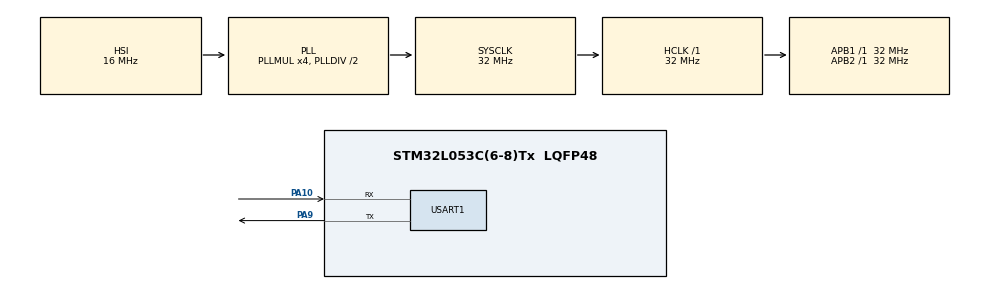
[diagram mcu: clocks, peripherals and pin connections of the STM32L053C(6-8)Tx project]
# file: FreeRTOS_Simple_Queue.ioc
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FREERTOS.Tasks01=defaultTask,0,128,StartDefaultTask,Default,NULL,Dynamic,NULL,NULL
Mcu.Family=STM32L0
Mcu.Name=STM32L053C(6-8)Tx
Mcu.Package=LQFP48
NVIC.TIM6_DAC_IRQn=true\:3\:0\:false\:false\:true\:false\:false\:true\:true
NVIC.TimeBase=TIM6_DAC_IRQn
NVIC.TimeBaseIP=TIM6
NVIC.USART1_IRQn=true\:3\:0\:false\:false\:true\:true\:true\:true\:true
PA10.Mode=Asynchronous
PA10.Signal=USART1_RX
PA9.Mode=Asynchronous
PA9.Signal=USART1_TX
ProjectManager.HeapSize=0x200
ProjectManager.StackSize=0x400
ProjectManager.TargetToolchain=STM32CubeIDE
RCC.AHBFreq_Value=32000000
RCC.APB1Freq_Value=32000000
RCC.APB1TimFreq_Value=32000000
RCC.APB2Freq_Value=32000000
RCC.APB2TimFreq_Value=32000000
RCC.HCLKFreq_Value=32000000
RCC.HSE_VALUE=8000000
RCC.HSI16_VALUE=16000000
RCC.HSI48MClockSelection=RCC_USBCLKSOURCE_HSI48
RCC.HSI48_VALUE=48000000
RCC.HSI_VALUE=16000000
RCC.LSE_VALUE=32768
RCC.MSI_VALUE=2097000
RCC.PLLMUL=RCC_PLLMUL_4
RCC.RTCClockSelectionVirtual=RCC_RTCCLKSOURCE_LSE
RCC.SYSCLKFreq_VALUE=32000000
RCC.SYSCLKSource=RCC_SYSCLKSOURCE_PLLCLK
RCC.VCOOutputFreq_Value=64000000
USART1.VirtualMode-Asynchronous=VM_ASYNC
VP_FREERTOS_VS_CMSIS_V1.Mode=CMSIS_V1
VP_SYS_VS_tim6.Mode=TIM6
board=STM32L0538-DISCO

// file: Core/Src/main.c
/* USER CODE BEGIN Header */
/**
 ******************************************************************************
 * @file           : main.c
 * @brief          : Main program body
 ******************************************************************************
 * @attention
 *
 * Copyright (c) 2023 STMicroelectronics.
 * All rights reserved.
 *
 * This software is licensed under terms that can be found in the LICENSE file
 * in the root directory of this software component.
 * If no LICENSE file comes with this software, it is provided AS-IS.
 *
 ******************************************************************************
 */
/* USER CODE END Header */
#include "main.h"

/* USER CODE BEGIN Includes */

#include "FreeRTOS.h"
#include "task.h"
#include "timers.h"
#include "queue.h"
#include "semphr.h"
#include "event_groups.h"

#include "string.h"
#include <stdio.h>
/* USER CODE END Includes */

UART_HandleTypeDef huart1;

/* USER CODE BEGIN PV */
uint8_t Rx_Data;
/* USER CODE END PV */

void SystemClock_Config(void);
static void MX_GPIO_Init(void);
static void MX_USART1_UART_Init(void);

/* USER CODE BEGIN 0 */

/************************* TASK HANDLERS **************************/
xTaskHandle Sender_HPT_Handler;
xTaskHandle Sender_LPT_Handler;
xTaskHandle Receiver_Handler;

/**********************  QUEUE HANDLER *********************/
xQueueHandle SimpleQueue;

/**********************  TASK FUNCTIONS *********************/
void Sender_HPT_Task(void *argument);
void Sender_LPT_Task(void *argument);
void Receiver_Task(void *argument);

/* USER CODE END 0 */

int main(void) {

	/* MCU Configuration--------------------------------------------------------*/

	/* Reset of all peripherals, Initializes the Flash interface and the Systick. */
	HAL_Init();

	/* Configure the system clock */
	SystemClock_Config();

	/* Initialize all configured peripherals */
	MX_GPIO_Init();
	MX_USART1_UART_Init();
	/* USER CODE BEGIN 2 */

	/**********************  Create Integer Queue *********************/
	SimpleQueue = xQueueCreate(5, sizeof(int));

	if (SimpleQueue == 0) {
		char *str = "OOPS!\r\nUnable ton create Integer Queue\r\n\r\n";
		HAL_UART_Transmit(&huart1, (uint8_t*) str, strlen(str), HAL_MAX_DELAY);
	} else {
		char *str = "Integer Queue created Successfully.\r\n\r\n";
		HAL_UART_Transmit(&huart1, (uint8_t*) str, strlen(str), HAL_MAX_DELAY);
	}

	/**********************  Create Task *********************/
	xTaskCreate(Sender_HPT_Task, "HPT_SEND", 128, NULL, 3, &Sender_HPT_Handler);
	xTaskCreate(Sender_LPT_Task, "LPT_SEND", 128, (void*) 111, 2,
			&Sender_LPT_Handler);
	xTaskCreate(Receiver_Task, "Receive", 128, NULL, 1, &Receiver_Handler);

	HAL_UART_Receive_IT(&huart1, &Rx_Data, 1);

	vTaskStartScheduler();

	/* USER CODE END 2 */

	/* Infinite loop */
	while (1) {

	}
}

void SystemClock_Config(void) {
	RCC_OscInitTypeDef RCC_OscInitStruct = { 0 };
	RCC_ClkInitTypeDef RCC_ClkInitStruct = { 0 };
	RCC_PeriphCLKInitTypeDef PeriphClkInit = { 0 };

	/** Configure the main internal regulator output voltage
	 */
	__HAL_PWR_VOLTAGESCALING_CONFIG(PWR_REGULATOR_VOLTAGE_SCALE1);

	/** Initializes the RCC Oscillators according to the specified parameters
	 * in the RCC_OscInitTypeDef structure.
	 */
	RCC_OscInitStruct.OscillatorType = RCC_OSCILLATORTYPE_HSI;
	RCC_OscInitStruct.HSIState = RCC_HSI_ON;
	RCC_OscInitStruct.HSICalibrationValue = RCC_HSICALIBRATION_DEFAULT;
	RCC_OscInitStruct.PLL.PLLState = RCC_PLL_ON;
	RCC_OscInitStruct.PLL.PLLSource = RCC_PLLSOURCE_HSI;
	RCC_OscInitStruct.PLL.PLLMUL = RCC_PLLMUL_4;
	RCC_OscInitStruct.PLL.PLLDIV = RCC_PLLDIV_2;
	if (HAL_RCC_OscConfig(&RCC_OscInitStruct) != HAL_OK) {
		Error_Handler();
	}

	/** Initializes the CPU, AHB and APB buses clocks
	 */
	RCC_ClkInitStruct.ClockType = RCC_CLOCKTYPE_HCLK | RCC_CLOCKTYPE_SYSCLK
			| RCC_CLOCKTYPE_PCLK1 | RCC_CLOCKTYPE_PCLK2;
	RCC_ClkInitStruct.SYSCLKSource = RCC_SYSCLKSOURCE_PLLCLK;
	RCC_ClkInitStruct.AHBCLKDivider = RCC_SYSCLK_DIV1;
	RCC_ClkInitStruct.APB1CLKDivider = RCC_HCLK_DIV1;
	RCC_ClkInitStruct.APB2CLKDivider = RCC_HCLK_DIV1;

	if (HAL_RCC_ClockConfig(&RCC_ClkInitStruct, FLASH_LATENCY_1) != HAL_OK) {
		Error_Handler();
	}
	PeriphClkInit.PeriphClockSelection = RCC_PERIPHCLK_USART1;
	PeriphClkInit.Usart1ClockSelection = RCC_USART1CLKSOURCE_PCLK2;
	if (HAL_RCCEx_PeriphCLKConfig(&PeriphClkInit) != HAL_OK) {
		Error_Handler();
	}
}

static void MX_USART1_UART_Init(void) {

	huart1.Instance = USART1;
	huart1.Init.BaudRate = 115200;
	huart1.Init.WordLength = UART_WORDLENGTH_8B;
	huart1.Init.StopBits = UART_STOPBITS_1;
	huart1.Init.Parity = UART_PARITY_NONE;
	huart1.Init.Mode = UART_MODE_TX_RX;
	huart1.Init.HwFlowCtl = UART_HWCONTROL_NONE;
	huart1.Init.OverSampling = UART_OVERSAMPLING_16;
	huart1.Init.OneBitSampling = UART_ONE_BIT_SAMPLE_DISABLE;
	huart1.AdvancedInit.AdvFeatureInit = UART_ADVFEATURE_NO_INIT;
	if (HAL_UART_Init(&huart1) != HAL_OK) {
		Error_Handler();
	}

}

static void MX_GPIO_Init(void) {

	/* GPIO Ports Clock Enable */
	__HAL_RCC_GPIOA_CLK_ENABLE();

}

/* USER CODE BEGIN 4 */

void Sender_HPT_Task(void *argument) {

	int i = 222;
	uint32_t TickDelay = pdMS_TO_TICKS(2000);
	while (1) {
		char *str =
				"Entered HPT Task\r\nAbout to send data to Integer Queue\r\n\r\n";
		HAL_UART_Transmit(&huart1, (uint8_t*) str, strlen(str), HAL_MAX_DELAY);

		if (xQueueSend(SimpleQueue, &i, portMAX_DELAY) == pdPASS) {
			char *str2 =
					"Successfully sent the number to the queue\r\nLeaving SENDER_HPT Task\r\n\r\n\r\n";
			HAL_UART_Transmit(&huart1, (uint8_t*) str2, strlen(str2),
			HAL_MAX_DELAY);
		}
		vTaskDelay(TickDelay);

	}
}
void Sender_LPT_Task(void *argument) {

	int ToSend;
	uint32_t TickDelay = pdMS_TO_TICKS(1000);
	while (1) {
		ToSend = (int) argument;
		char *str =
				"Entered LPT Task\r\nAbout to send data to Integer Queue\r\n\r\n";
		HAL_UART_Transmit(&huart1, (uint8_t*) str, strlen(str), HAL_MAX_DELAY);

		xQueueSend(SimpleQueue, &ToSend, portMAX_DELAY);

		char *str2 =
				"Successfully sent the number to the queue\r\nLeaving SENDER_LPT Task\r\n\r\n\r\n";
		HAL_UART_Transmit(&huart1, (uint8_t*) str2, strlen(str2),
		HAL_MAX_DELAY);

		vTaskDelay(TickDelay);

	}

}
void Receiver_Task(void *argument) {

	int received=0;
		uint32_t TickDelay = pdMS_TO_TICKS(3000);
		while (1)
		{
			char str[100];
			if (xQueueReceive(SimpleQueue, &received, portMAX_DELAY) != pdTRUE)
			{
				HAL_UART_Transmit(&huart1, (uint8_t *)"Error in Receiving from Queue\r\n\r\n", 31, 1000);
			}
			else
			{
				sprintf(str, " Successfully RECEIVED the number %d to the queue\r\nLeaving RECEIVER Task\r\n\r\n\r\n",received);
				HAL_UART_Transmit(&huart1, (uint8_t *)str, strlen (str), HAL_MAX_DELAY);
			}
			vTaskDelay(TickDelay);
		}
}

void HAL_UART_RxCpltCallback(UART_HandleTypeDef *huart)
{
	HAL_UART_Receive_IT(huart, &Rx_Data, 1);
	int ToSend = 123456789;
	if (Rx_Data == 'r')
	{
		 /* The xHigherPriorityTaskWoken parameter must be initialized to pdFALSE as
		 it will get set to pdTRUE inside the interrupt safe API function if a
		 context switch is required. */
		BaseType_t xHigherPriorityTaskWoken = pdFALSE;

		if (xQueueSendToFrontFromISR(SimpleQueue, &ToSend, &xHigherPriorityTaskWoken) == pdPASS)
		{
			HAL_UART_Transmit(huart, (uint8_t *)"\r\n\r\nSent from ISR\r\n\r\n\r\n", 23, 500);
		}

		/* Pass the xHigherPriorityTaskWoken value into portEND_SWITCHING_ISR(). If
		 xHigherPriorityTaskWoken was set to pdTRUE inside xSemaphoreGiveFromISR()
		 then calling portEND_SWITCHING_ISR() will request a context switch. If
		 xHigherPriorityTaskWoken is still pdFALSE then calling
		 portEND_SWITCHING_ISR() will have no effect */

		portEND_SWITCHING_ISR(xHigherPriorityTaskWoken);
	}
}
	/* USER CODE END 4 */

	/**
	 * @brief  Period elapsed callback in non blocking mode
	 * @note   This function is called  when TIM6 interrupt took place, inside
	 * HAL_TIM_IRQHandler(). It makes a direct call to HAL_IncTick() to increment
	 * a global variable "uwTick" used as application time base.
	 * @param  htim : TIM handle
	 * @retval None
	 */
	void HAL_TIM_PeriodElapsedCallback(TIM_HandleTypeDef *htim) {
		if (htim->Instance == TIM6) {
			HAL_IncTick();
		}
	}

	/**
	 * @brief  This function is executed in case of error occurrence.
	 * @retval None
	 */
	void Error_Handler(void) {
		__disable_irq();
		while (1) {
		}
	}
